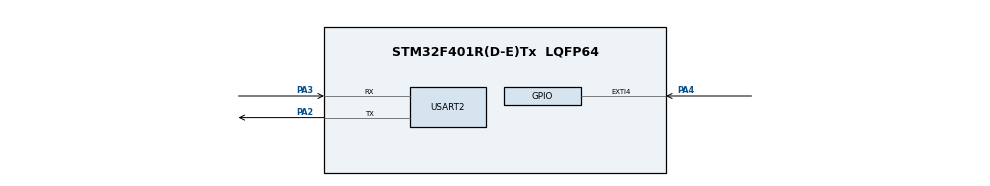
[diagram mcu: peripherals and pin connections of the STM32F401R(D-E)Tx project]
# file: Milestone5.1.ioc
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Mcu.Family=STM32F4
Mcu.Name=STM32F401R(D-E)Tx
Mcu.Package=LQFP64
NVIC.EXTI4_IRQn=true\:0\:0\:false\:false\:true\:true\:true\:true
NVIC.PriorityGroup=NVIC_PRIORITYGROUP_4
PA2.Mode=Asynchronous
PA2.Signal=USART2_TX
PA3.Mode=Asynchronous
PA3.Signal=USART2_RX
PA4.GPIO_ModeDefaultEXTI=GPIO_MODE_IT_FALLING
PA4.GPIO_PuPd=GPIO_PULLUP
PA4.Signal=GPXTI4
ProjectManager.HeapSize=0x200
ProjectManager.StackSize=0x400
ProjectManager.TargetToolchain=Makefile
RCC.AHBFreq_Value=16000000
RCC.APB1Freq_Value=16000000
RCC.APB2Freq_Value=16000000
RCC.CortexFreq_Value=16000000
RCC.HSE_VALUE=25000000
RCC.HSI_VALUE=16000000
RCC.LSE_VALUE=32768
RCC.SYSCLKFreq_VALUE=16000000
RCC.VCOOutputFreq_Value=192000000
USART2.VirtualMode=VM_ASYNC
board=custom

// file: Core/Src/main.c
/* USER CODE BEGIN Header */
/**
  ******************************************************************************
  * @file           : main.c
  * @brief          : Main program body
  ******************************************************************************
  * @attention
  *
  * Copyright (c) 2026 STMicroelectronics.
  * All rights reserved.
  *
  * This software is licensed under terms that can be found in the LICENSE file
  * in the root directory of this software component.
  * If no LICENSE file comes with this software, it is provided AS-IS.
  *
  ******************************************************************************
  */
/* USER CODE END Header */
#include "main.h"

/* USER CODE BEGIN PD */
// void UART_SendAndReadData(USART_TypeDef *USARTX, const uint8_t *data, size_t length);
/* USER CODE END PD */

void SystemClock_Config(void);
static void MX_GPIO_Init(void);
static void MX_USART2_UART_Init(void);

int main(void)
{

  /* MCU Configuration--------------------------------------------------------*/

  /* Reset of all peripherals, Initializes the Flash interface and the Systick. */
  LL_APB2_GRP1_EnableClock(LL_APB2_GRP1_PERIPH_SYSCFG);
  LL_APB1_GRP1_EnableClock(LL_APB1_GRP1_PERIPH_PWR);

  /* System interrupt init*/
  NVIC_SetPriorityGrouping(NVIC_PRIORITYGROUP_4);

  /* SysTick_IRQn interrupt configuration */
  NVIC_SetPriority(SysTick_IRQn, NVIC_EncodePriority(NVIC_GetPriorityGrouping(),15, 0));

  /* Configure the system clock */
  SystemClock_Config();

  /* Initialize all configured peripherals */
  MX_GPIO_Init();
  MX_USART2_UART_Init();
const char *test_msg = "UART BOOT OK\r\n";
UART_SendAndReadData(USART2, (const uint8_t *)test_msg, strlen(test_msg));
  /* Infinite loop */
  while (1)
  {

  }
}

void SystemClock_Config(void)
{
  LL_FLASH_SetLatency(LL_FLASH_LATENCY_0);
  while(LL_FLASH_GetLatency()!= LL_FLASH_LATENCY_0)
  {
  }
  LL_PWR_SetRegulVoltageScaling(LL_PWR_REGU_VOLTAGE_SCALE2);
  LL_RCC_HSI_SetCalibTrimming(16);
  LL_RCC_HSI_Enable();

   /* Wait till HSI is ready */
  while(LL_RCC_HSI_IsReady() != 1)
  {

  }
  LL_RCC_SetAHBPrescaler(LL_RCC_SYSCLK_DIV_1);
  LL_RCC_SetAPB1Prescaler(LL_RCC_APB1_DIV_1);
  LL_RCC_SetAPB2Prescaler(LL_RCC_APB2_DIV_1);
  LL_RCC_SetSysClkSource(LL_RCC_SYS_CLKSOURCE_HSI);

   /* Wait till System clock is ready */
  while(LL_RCC_GetSysClkSource() != LL_RCC_SYS_CLKSOURCE_STATUS_HSI)
  {

  }
  LL_Init1msTick(16000000);
  LL_SetSystemCoreClock(16000000);
  LL_RCC_SetTIMPrescaler(LL_RCC_TIM_PRESCALER_TWICE);
}

static void MX_USART2_UART_Init(void)
{

  LL_USART_InitTypeDef USART_InitStruct = {0};

  LL_GPIO_InitTypeDef GPIO_InitStruct = {0};

  /* Peripheral clock enable */
  LL_APB1_GRP1_EnableClock(LL_APB1_GRP1_PERIPH_USART2);

  LL_AHB1_GRP1_EnableClock(LL_AHB1_GRP1_PERIPH_GPIOA);
  /**USART2 GPIO Configuration
  PA2   ------> USART2_TX
  PA3   ------> USART2_RX
  */
  GPIO_InitStruct.Pin = LL_GPIO_PIN_2|LL_GPIO_PIN_3;
  GPIO_InitStruct.Mode = LL_GPIO_MODE_ALTERNATE;
  GPIO_InitStruct.Speed = LL_GPIO_SPEED_FREQ_VERY_HIGH;
  GPIO_InitStruct.OutputType = LL_GPIO_OUTPUT_PUSHPULL;
  GPIO_InitStruct.Pull = LL_GPIO_PULL_NO;
  GPIO_InitStruct.Alternate = LL_GPIO_AF_7;
  LL_GPIO_Init(GPIOA, &GPIO_InitStruct);

  USART_InitStruct.BaudRate = 115200;
  USART_InitStruct.DataWidth = LL_USART_DATAWIDTH_8B;
  USART_InitStruct.StopBits = LL_USART_STOPBITS_1;
  USART_InitStruct.Parity = LL_USART_PARITY_NONE;
  USART_InitStruct.TransferDirection = LL_USART_DIRECTION_TX_RX;
  USART_InitStruct.HardwareFlowControl = LL_USART_HWCONTROL_NONE;
  USART_InitStruct.OverSampling = LL_USART_OVERSAMPLING_16;
  LL_USART_Init(USART2, &USART_InitStruct);
  LL_USART_ConfigAsyncMode(USART2);
  LL_USART_Enable(USART2);

}

static void MX_GPIO_Init(void)
{
  LL_EXTI_InitTypeDef EXTI_InitStruct = {0};
  /* USER CODE BEGIN MX_GPIO_Init_1 */
  LL_APB2_GRP1_EnableClock(LL_APB2_GRP1_PERIPH_SYSCFG);
  /* USER CODE END MX_GPIO_Init_1 */

  /* GPIO Ports Clock Enable */
  LL_AHB1_GRP1_EnableClock(LL_AHB1_GRP1_PERIPH_GPIOA);

  /**/
  LL_SYSCFG_SetEXTISource(LL_SYSCFG_EXTI_PORTA, LL_SYSCFG_EXTI_LINE4);

  /**/
  EXTI_InitStruct.Line_0_31 = LL_EXTI_LINE_4;
  EXTI_InitStruct.LineCommand = ENABLE;
  EXTI_InitStruct.Mode = LL_EXTI_MODE_IT;
  EXTI_InitStruct.Trigger = LL_EXTI_TRIGGER_FALLING;
  LL_EXTI_Init(&EXTI_InitStruct);

  /**/
  LL_GPIO_SetPinPull(GPIOA, LL_GPIO_PIN_4, LL_GPIO_PULL_UP);

  /**/
  LL_GPIO_SetPinMode(GPIOA, LL_GPIO_PIN_4, LL_GPIO_MODE_INPUT);

  /* EXTI interrupt init*/
  NVIC_SetPriority(EXTI4_IRQn, NVIC_EncodePriority(NVIC_GetPriorityGrouping(),0, 0));
  NVIC_EnableIRQ(EXTI4_IRQn);

}

void Error_Handler(void)
{
  __disable_irq();
  while (1)
  {
  }
}
